# AM13E230x register map
Vendor: Texas Instruments; File version: Revised: 2025-12-26 17:30:06
CPU: CM33 r0p0, little endian, MPU, FPU, 4 interrupt priority bits
Registers are 32-bit, read-write, reset 0x0 unless marked. A register's access mark holds for its fields unless they carry their own. Offsets are from the block's base; [hi:lo] are bit positions; lines under a group give offsets from that group; {n}, {i} and the like mark numbered series; 'fields as' and 'values as' point back to an identical list.

## GPIO0 — PERIPHERALREGION
Base 0x400F0000
Same registers: GPIO1 0x400F2000, GPIO2 0x400F4000, GPIO3 0x400F6000
{0x800+0x18*i} GPRCM[{i}] (i=0..0) group
  0x00 PWREN — Power enable
    [0] ENABLE — Power Enable
      0=DISABLE (Disable Power); 1=ENABLE (Enable Power)
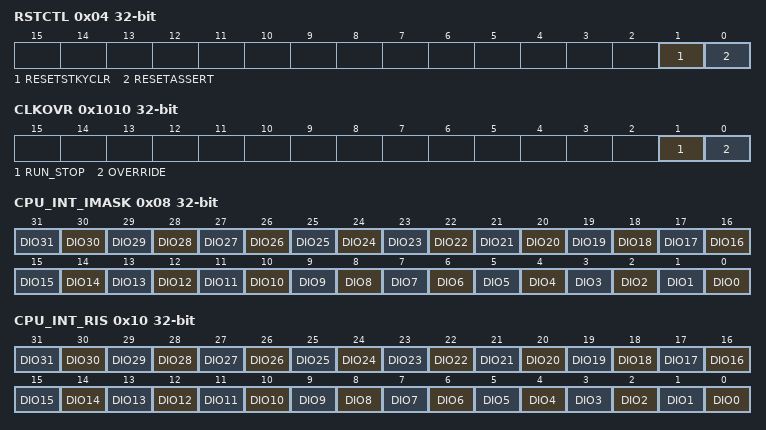
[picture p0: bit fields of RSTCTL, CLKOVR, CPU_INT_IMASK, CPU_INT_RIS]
  0x04 RSTCTL wo — Reset Control
    [1] RESETSTKYCLR — Reset sticky bit clear
      0=NOP (Writing 0 has no effect); 1=CLR (Clear reset sticky bit)
    [0] RESETASSERT — Reset assertion to the peripheral
      0=NOP (Writing 0 has no effect); 1=ASSERT (Assert reset)
  0x14 STAT ro — Status Register
    [16] RESETSTKY — Reset sticky bit
      0=NORES (The peripheral has not been reset since this bit was last cleared by RESETSTKYCLR in the RSTCTL register); 1=RESET (The peripheral was reset since the last bit clear)
0x1010 CLKOVR — Clock Override
  [1] RUN_STOP — If [OVERRIDE] is enabled, this register is used to manually control the peripheral's clock request to the system
    0=RUN (Run/ungate functional clock); 1=STOP (Stop/gate functional clock)
  [0] OVERRIDE — Unlocks the functionality of [RUN_STOP] to override the automatic peripheral clock request
    0=DISABLED (Override disabled); 1=ENABLED (Override enabled)
0x1018 PDBGCTL reset 0x1 — Peripheral Debug Control
  [0] FREE — Free run control
    0=STOP (The peripheral freezes functionality while the Core Halted input is asserted and resumes when it is deasserted.); 1=RUN (The peripheral ignores the state of the Core Halted input)
{0x1020+0x2C*i} CPU_INT[{i}] (i=0..0) group
  0x00 CPU_INT_IIDX ro — Interrupt index
    [7:0] STAT — Interrupt index status
      0=NO_INTR (No bit is set means there is no pending interrupt request); {v}=DIO{v-1} (DIO{v-1} interrupt) (v=1..32)
  0x08 CPU_INT_IMASK — Interrupt mask
    [all] fields
      0=CLR (Event is masked); 1=SET (Event is unmasked)
    [n] DIO{n} (n=0..31) — DIO{n} event mask
  0x10 CPU_INT_RIS ro — Raw interrupt status
    [n] DIO{n} (n=0..31) — DIO{n} event
      0=CLR (DIO{n} event did not occur); 1=SET (DIO{n} event occurred)
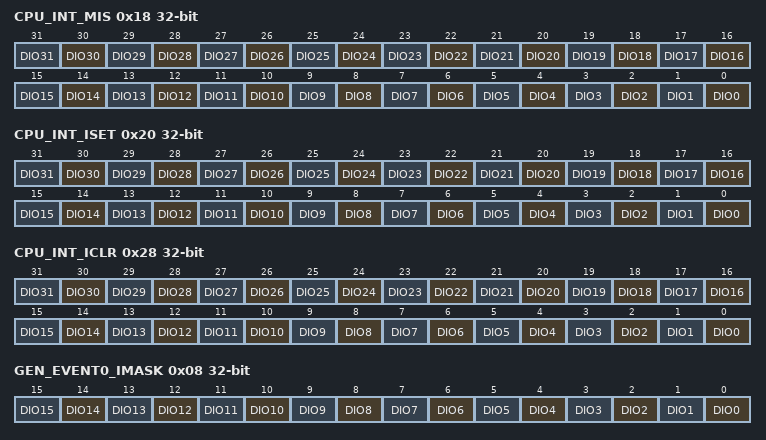
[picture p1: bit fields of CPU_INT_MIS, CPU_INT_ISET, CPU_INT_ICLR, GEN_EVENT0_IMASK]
  0x18 CPU_INT_MIS ro — Masked interrupt status
    fields as CPU_INT[0].CPU_INT_RIS
  0x20 CPU_INT_ISET wo — Interrupt set
    [n] DIO{n} (n=0..31) — DIO{n} event
      0=NO_EFFECT; 1=SET (Sets DIO{n} in RIS register)
  0x28 CPU_INT_ICLR wo — Interrupt clear
    [n] DIO{n} (n=0..31) — DIO{n} event
      0=NO_EFFECT; 1=CLR (Clears DIO{n} in RIS register)
{0x1050+0x2C*i} GEN_EVENT0[{i}] (i=0..0) group
  0x00 GEN_EVENT0_IIDX ro — Interrupt index
    [7:0] STAT — Interrupt index status
      0=NO_INTR (No bit is set means there is no pending interrupt request); {v}=DIO{v-1} (DIO{v-1} interrupt) (v=1..16)
  0x08 GEN_EVENT0_IMASK — Interrupt mask
    [all] fields
      0=CLR (Event is masked); 1=SET (Event is unmasked)
    [n] DIO{n} (n=0..15) — DIO{n} event mask
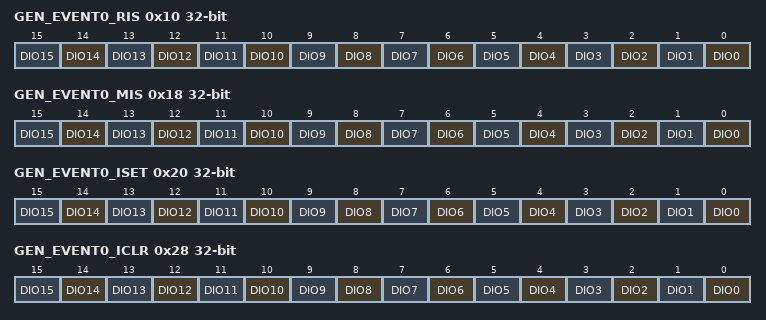
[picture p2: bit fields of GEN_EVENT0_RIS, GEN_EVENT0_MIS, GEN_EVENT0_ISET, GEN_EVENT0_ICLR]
  0x10 GEN_EVENT0_RIS ro — Raw interrupt status
    [n] DIO{n} (n=0..15) — DIO{n} event
      values as CPU_INT[0].CPU_INT_RIS.DIO0
  0x18 GEN_EVENT0_MIS ro — Masked interrupt status
    fields as GEN_EVENT0[0].GEN_EVENT0_RIS
  0x20 GEN_EVENT0_ISET wo — Interrupt set
    [n] DIO{n} (n=0..15) — DIO{n} event
      0=NO_EFFECT; 1=SET (Sets DIO{n} in RIS register)
  0x28 GEN_EVENT0_ICLR wo — Interrupt clear
    [n] DIO{n} (n=0..15) — DIO{n} event
      0=NO_EFFECT; 1=CLR (Clears DIO{n} in RIS register)
{0x1080+0x2C*i} GEN_EVENT1[{i}] (i=0..0) group
  0x00 GEN_EVENT1_IIDX ro — Interrupt index
    [7:0] STAT — Interrupt index status
      0=NO_INTR (No bit is set means there is no pending interrupt request); {v}=DIO{v+15} (DIO{v-1} interrupt) (v=1..16)
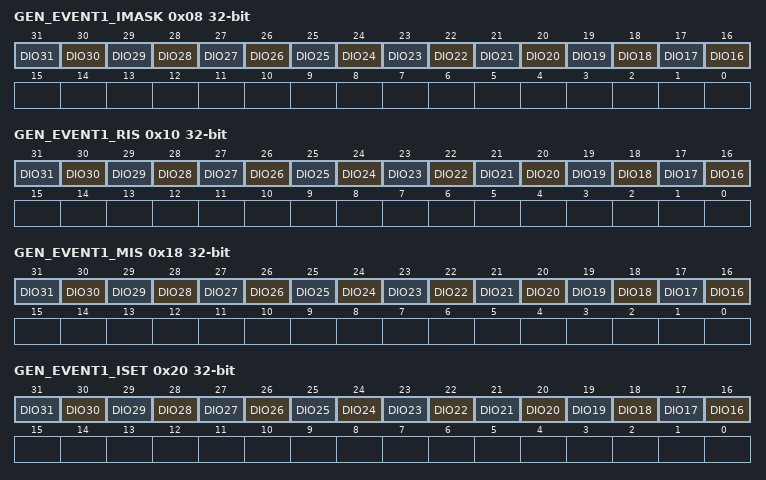
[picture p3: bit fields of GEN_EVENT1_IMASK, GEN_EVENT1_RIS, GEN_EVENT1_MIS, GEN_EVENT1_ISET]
  0x08 GEN_EVENT1_IMASK — Interrupt mask
    [all] fields
      0=CLR (Event is masked); 1=SET (Event is unmasked)
    [n] DIO{n} (n=16..31) — DIO{n} event mask
  0x10 GEN_EVENT1_RIS ro — Raw interrupt status
    [n] DIO{n} (n=16..31) — DIO{n} event
      values as CPU_INT[0].CPU_INT_RIS.DIO0
  0x18 GEN_EVENT1_MIS ro — Masked interrupt status
    fields as GEN_EVENT1[0].GEN_EVENT1_RIS
  0x20 GEN_EVENT1_ISET wo — Interrupt set
    [n] DIO{n} (n=16..31) — DIO{n} event
      0=NO_EFFECT; 1=SET (Sets DIO{n} in RIS register)
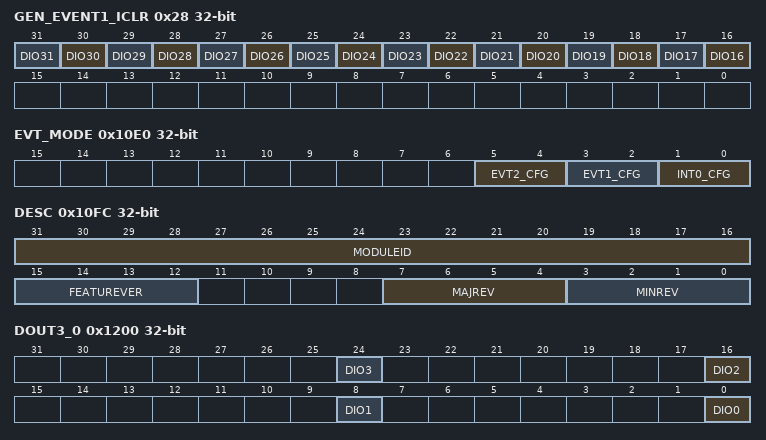
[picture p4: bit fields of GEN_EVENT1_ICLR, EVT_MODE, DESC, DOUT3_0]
  0x28 GEN_EVENT1_ICLR wo — Interrupt clear
    [n] DIO{n} (n=16..31) — DIO{n} event
      0=NO_EFFECT; 1=CLR (Clears DIO{n} in RIS register)
0x10E0 EVT_MODE — Event Mode
  [all] fields
    0=DISABLE (The interrupt or event line is disabled.); 1=SOFTWARE (The interrupt or event line is in software mode. Software must clear the RIS.); 2=HARDWARE (The interrupt or event line is in hardware mode. The hardware (another module) clears automatically the associated RIS flag.)
  [5:4] EVT2_CFG ro — Event line mode select for event corresponding to [IPSTANDARD.GEN_EVENT1]
  [3:2] EVT1_CFG ro — Event line mode select for event corresponding to [IPSTANDARD.GEN_EVENT0]
  [1:0] INT0_CFG ro — Event line mode select for event corresponding to [IPSTANDARD.CPU_INT]
0x10FC DESC ro — Module Description
  [31:16] MODULEID — Module identification contains a unique peripheral identification number. The assignments are maintained in a central database for all of the platform modules to ensure uniqueness.
  [15:12] FEATUREVER — Feature Set for the module *instance*
  [7:4] MAJREV — Major rev of the IP
  [3:0] MINREV — Minor rev of the IP
0x1200 DOUT3_0 wo — Data output 3 to 0
  [all] fields
    0=ZERO (Output is set to 0); 1=ONE (Output is set to 1)
  [8n] DIO{n} (n=0..3) — This bit sets the value of the pin configured as DIO{n} when the output is enabled through DOE31_0 register.
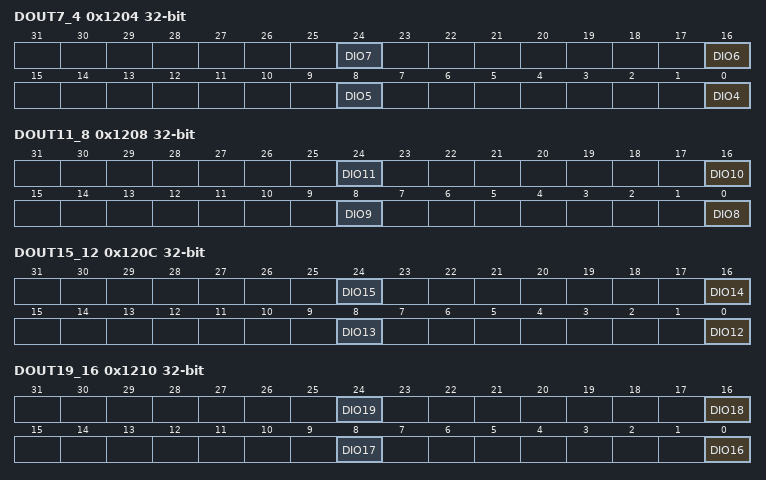
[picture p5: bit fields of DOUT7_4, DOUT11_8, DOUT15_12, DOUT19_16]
0x1204 DOUT7_4 wo — Data output 7 to 4
  [all] fields
    0=ZERO (Output is set to 0); 1=ONE (Output is set to 1)
  [8n-32] DIO{n} (n=4..7) — This bit sets the value of the pin configured as DIO{n} when the output is enabled through DOE31_0 register.
0x1208 DOUT11_8 wo — Data output 11 to 8
  [all] fields
    0=ZERO (Output is set to 0); 1=ONE (Output is set to 1)
  [8n-64] DIO{n} (n=8..11) — This bit sets the value of the pin configured as DIO{n} when the output is enabled through DOE31_0 register.
0x120C DOUT15_12 wo — Data output 15 to 12
  [all] fields
    0=ZERO (Output is set to 0); 1=ONE (Output is set to 1)
  [8n-96] DIO{n} (n=12..15) — This bit sets the value of the pin configured as DIO{n} when the output is enabled through DOE31_0 register.
0x1210 DOUT19_16 wo — Data output 19 to 16
  [all] fields
    0=ZERO (Output is set to 0); 1=ONE (Output is set to 1)
  [8n-128] DIO{n} (n=16..19) — This bit sets the value of the pin configured as DIO{n} when the output is enabled through DOE31_0 register.
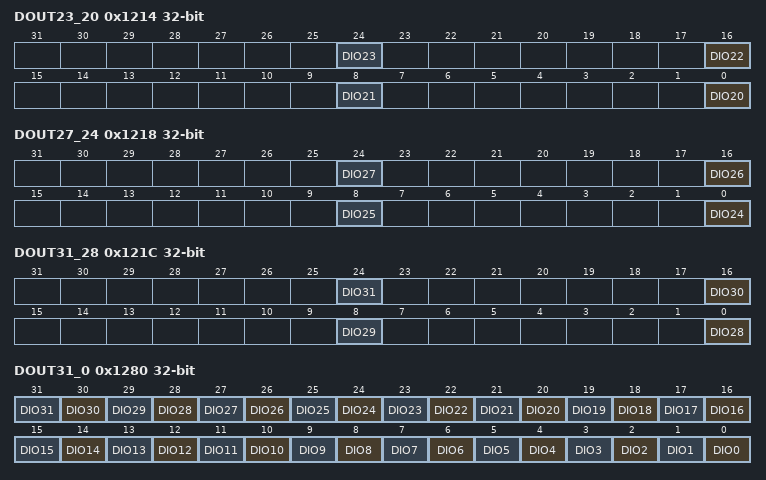
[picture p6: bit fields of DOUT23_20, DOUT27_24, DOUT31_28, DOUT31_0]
0x1214 DOUT23_20 wo — Data output 23 to 20
  [all] fields
    0=ZERO (Output is set to 0); 1=ONE (Output is set to 1)
  [8n-160] DIO{n} (n=20..23) — This bit sets the value of the pin configured as DIO{n} when the output is enabled through DOE31_0 register.
0x1218 DOUT27_24 wo — Data output 27 to 24
  [all] fields
    0=ZERO (Output is set to 0); 1=ONE (Output is set to 1)
  [8n-192] DIO{n} (n=24..27) — This bit sets the value of the pin configured as DIO{n} when the output is enabled through DOE31_0 register.
0x121C DOUT31_28 wo — Data output 31 to 28
  [all] fields
    0=ZERO (Output is set to 0); 1=ONE (Output is set to 1)
  [8n-224] DIO{n} (n=28..31) — This bit sets the value of the pin configured as DIO{n} when the output is enabled through DOE31_0 register.
0x1280 DOUT31_0 — Data output 31 to 0
  [all] fields
    0=ZERO (Output is set to 0); 1=ONE (Output is set to 1)
  [n] DIO{n} (n=0..31) — This bit sets the value of the pin configured as DIO{n} when the output is enabled through DOE31_0 register.
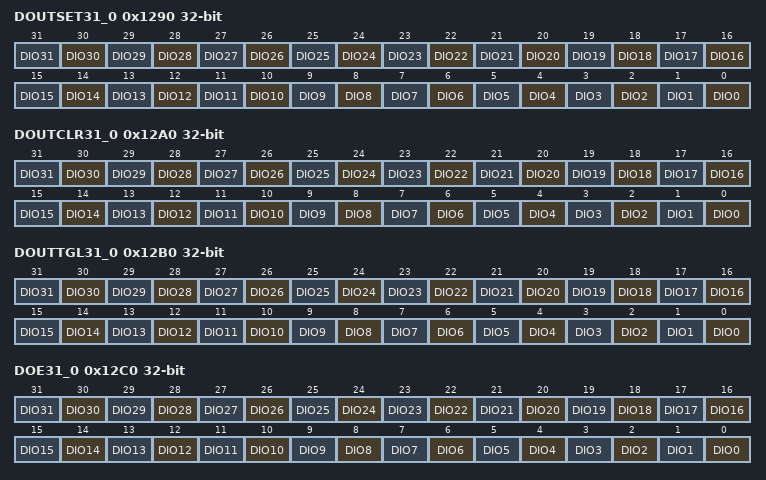
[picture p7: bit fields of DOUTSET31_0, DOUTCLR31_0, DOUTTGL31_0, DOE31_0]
0x1290 DOUTSET31_0 wo — Data output set 31 to 0
  [n] DIO{n} (n=0..31) — Writing 1 to this bit sets the DIO{n} bit in the DOUT31_0 register. Writing 0 has no effect.
    0=NO_EFFECT; 1=SET (Sets DIO{n} in DOUT31_0)
0x12A0 DOUTCLR31_0 wo — Data output clear 31 to 0
  [n] DIO{n} (n=0..31) — Writing 1 to this bit clears the DIO{n} bit in the DOUT31_0 register. Writing 0 has no effect.
    0=NO_EFFECT; 1=CLR (Clears DIO{n} in DOUT31_0)
0x12B0 DOUTTGL31_0 wo — Data output toggle 31 to 0
  [all] fields
    0=NO_EFFECT; 1=TOGGLE (Toggle output)
  [n] DIO{n} (n=0..31) — This bit is used to toggle DIO{n} output.
0x12C0 DOE31_0 — Data output enable 31 to 0
  [all] fields
    0=DISABLE (Output disabled); 1=ENABLE (Output enabled)
  [n] DIO{n} (n=0..31) — Enables data output for DIO{n}.
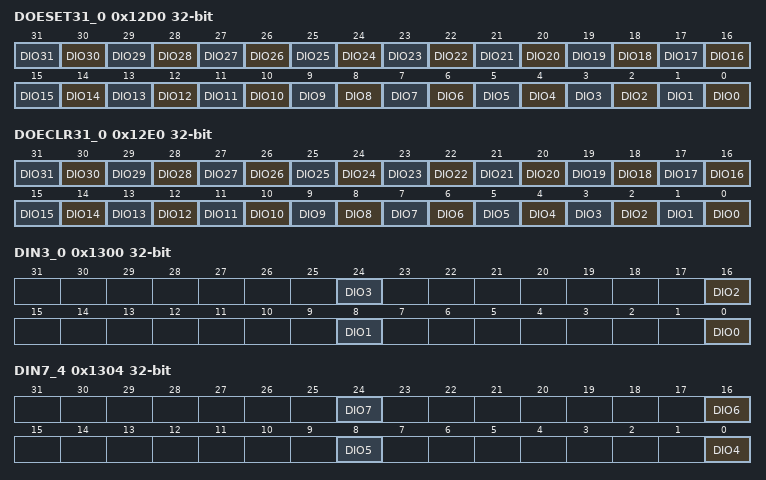
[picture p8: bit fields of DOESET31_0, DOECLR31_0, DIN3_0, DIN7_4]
0x12D0 DOESET31_0 wo — Data output enable set 31 to 0
  [n] DIO{n} (n=0..31) — Writing 1 to this bit sets the DIO{n} bit in the DOE31_0 register. Writing 0 has no effect.
    0=NO_EFFECT; 1=SET (Sets DIO{n} in DOE31_0)
0x12E0 DOECLR31_0 wo — Data output enable clear 31 to 0
  [n] DIO{n} (n=0..31) — Writing 1 to this bit clears the DIO{n} bit in the DOE31_0 register. Writing 0 has no effect.
    0=NO_EFFECT; 1=CLR (Clears DIO{n} in DOE31_0)
0x1300 DIN3_0 ro — Data input 3 to 0
  [all] fields
    0=ZERO (Input value is 0); 1=ONE (Input value is 1)
  [8n] DIO{n} (n=0..3) — This bit reads the data input value of DIO{n}.
0x1304 DIN7_4 ro — Data input 7 to 4
  [all] fields
    0=ZERO (Input value is 0); 1=ONE (Input value is 1)
  [8n-32] DIO{n} (n=4..7) — This bit reads the data input value of DIO{n}.
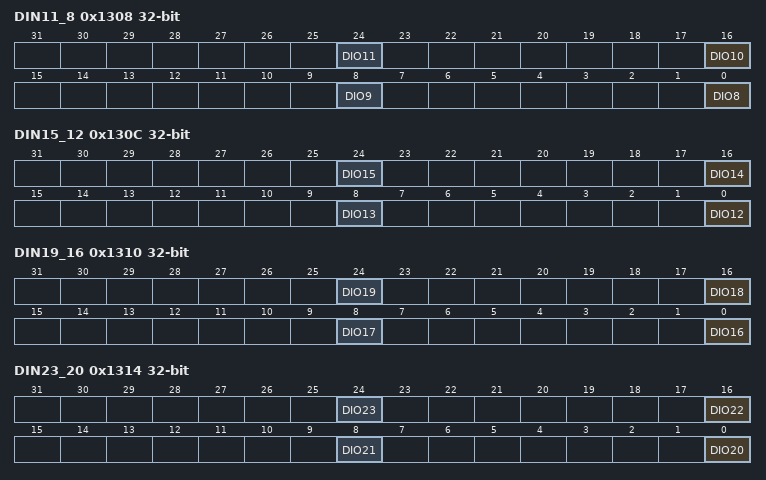
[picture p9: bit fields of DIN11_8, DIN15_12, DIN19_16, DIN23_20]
0x1308 DIN11_8 ro — Data input 11 to 8
  [all] fields
    0=ZERO (Input value is 0); 1=ONE (Input value is 1)
  [8n-64] DIO{n} (n=8..11) — This bit reads the data input value of DIO{n}.
0x130C DIN15_12 ro — Data input 15 to 12
  [all] fields
    0=ZERO (Input value is 0); 1=ONE (Input value is 1)
  [8n-96] DIO{n} (n=12..15) — This bit reads the data input value of DIO{n}.
0x1310 DIN19_16 ro — Data input 19 to 16
  [all] fields
    0=ZERO (Input value is 0); 1=ONE (Input value is 1)
  [8n-128] DIO{n} (n=16..19) — This bit reads the data input value of DIO{n}.
0x1314 DIN23_20 ro — Data input 23 to 20
  [all] fields
    0=ZERO (Input value is 0); 1=ONE (Input value is 1)
  [8n-160] DIO{n} (n=20..23) — This bit reads the data input value of DIO{n}.
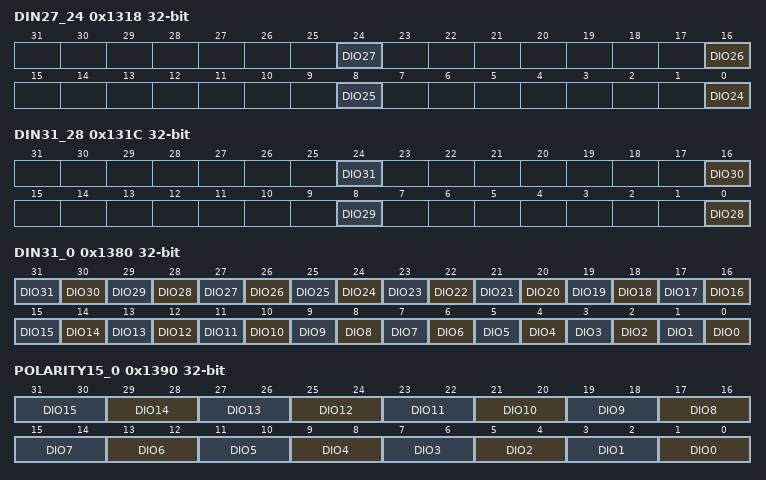
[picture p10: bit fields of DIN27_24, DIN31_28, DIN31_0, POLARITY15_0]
0x1318 DIN27_24 ro — Data input 27 to 24
  [all] fields
    0=ZERO (Input value is 0); 1=ONE (Input value is 1)
  [8n-192] DIO{n} (n=24..27) — This bit reads the data input value of DIO{n}.
0x131C DIN31_28 ro — Data input 31 to 28
  [all] fields
    0=ZERO (Input value is 0); 1=ONE (Input value is 1)
  [8n-224] DIO{n} (n=28..31) — This bit reads the data input value of DIO{n}.
0x1380 DIN31_0 ro — Data input 31 to 0
  [all] fields
    0=ZERO (Input value is 0); 1=ONE (Input value is 1)
  [n] DIO{n} (n=0..31) — This bit reads the data input value of DIO{n}.
0x1390 POLARITY15_0 — Polarity 15 to 0
  [all] fields
    0=DISABLE (Edge detection disabled); 1=RISE (Detects rising edge of input event); 2=FALL (Detects falling edge of input event); 3=RISE_FALL (Detects both rising and falling edge of input event)
  [2n+1:2n] DIO{n} (n=0..15) — Enables and configures edge detection polarity for DIO{n}.
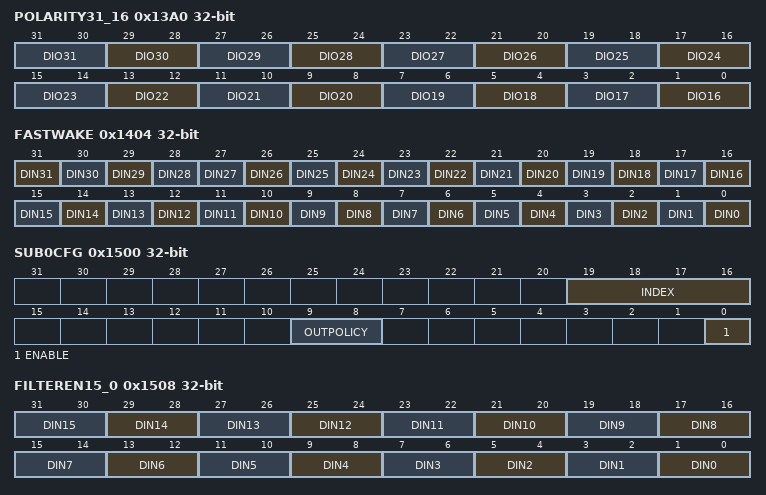
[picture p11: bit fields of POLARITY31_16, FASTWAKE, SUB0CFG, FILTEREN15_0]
0x13A0 POLARITY31_16 — Polarity 31 to 16
  [all] fields
    values as the fields of POLARITY15_0
  [2n-31:2n-32] DIO{n} (n=16..31) — Enables and configures edge detection polarity for DIO{n}.
0x1400 CTL — FAST WAKE GLOBAL EN
  [0] FASTWAKEONLY — FASTWAKEONLY for the global control of fastwake
    0=NOT_GLOBAL_EN (The global control of fastwake is not enabled, per bit fast wake feature depends on FASTWAKE.DIN); 1=GLOBAL_EN (The global control of fastwake is enabled)
0x1404 FASTWAKE — FAST WAKE ENABLE
  [all] fields
    0=DISABLE (fastwake feature is disabled); 1=ENABLE (fastwake feature is enabled)
  [31] DIN31 — Enable fastwake feature for DIN31
  [30] DIN30 — Enable fastwake feature for DIN30
  [29] DIN29 — Enable fastwake feature for DIN29
  [28] DIN28 — Enable fastwake feature for DIN29
  [n] DIN{n} (n=0..27) — Enable fastwake feature for DIN{n}
0x1500 SUB0CFG — Subscriber 0 configuration
  [19:16] INDEX — Indicates the specific bit among lower 16 bits that is targeted by the subscriber action
    0=MIN (specific bit targeted by the subscriber action is bit0); 15=MAX (specific bit targeted by the subscriber action is bit15)
  [9:8] OUTPOLICY — These bits configure the output policy for subscriber 0 event.
    0=SET (Selected DIO pins are set); 1=CLR (Selected DIO pins are cleared); 2=TOGGLE (Selected DIO pins are toggled)
  [0] ENABLE — This bit is used to enable subscriber 0 event.
    0=CLR (Subscriber 0 event is disabled); 1=SET (Subscriber 0 event is enabled)
0x1508 FILTEREN15_0 — Filter Enable 15 to 0
  [all] fields
    0=DISABLE (No additional filter beyond the CDC synchronization sample); 1=ONE_CYCLE (1 ULPCLK minimum sample); 2=THREE_CYCLE (3 ULPCLK minimum sample); 3=EIGHT_CYCLE (8 ULPCLK minimum sample)
  [2n+1:2n] DIN{n} (n=0..15) — Programmable counter length of digital glitch filter for DIN{n}
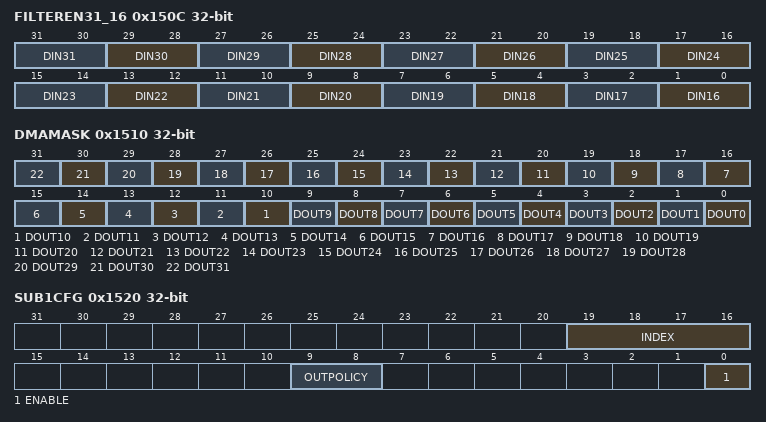
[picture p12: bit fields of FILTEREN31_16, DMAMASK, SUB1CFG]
0x150C FILTEREN31_16 — Filter Enable 31 to 16
  [all] fields
    values as the fields of FILTEREN15_0
  [2n-31:2n-32] DIN{n} (n=16..31) — Programmable counter length of digital glitch filter for DIN{n}
0x1510 DMAMASK — DMA Write MASK
  [all] fields
    0=DISABLE (DMA is not allowed to modify this bit lane); 1=ENABLE (DMA is allowed to modify this bit lane)
  [n] DOUT{n} (n=0..31) — DMA is allowed to modify DOUT{n}
0x1520 SUB1CFG — Subscriber 1 configuration
  [19:16] INDEX — indicates the specific bit in the upper 16 bits that is targeted by the subscriber action
    0=MIN (specific bit targeted by the subscriber action is bit16); 15=MAX (specific bit targeted by the subscriber action is bit31)
  [9:8] OUTPOLICY — These bits configure the output policy for subscriber 1 event.
    values as SUB0CFG.OUTPOLICY
  [0] ENABLE — This bit is used to enable subscriber 1 event.
    0=CLR (Subscriber 1 event is disabled); 1=SET (Subscriber 1 event is enabled)
